# GD32E511_512 register map
File version: 1.0
CPU: CM33 r0p4, little endian, MPU, FPU, 4 interrupt priority bits
Registers are 32-bit, read-write, reset 0x0 unless marked. A register's access mark holds for its fields unless they carry their own. Offsets are from the block's base; [hi:lo] are bit positions.

## CRC — cyclic redundancy check calculation unit
Base 0x40023000
0x00 DATA reset 0xFFFFFFFF
  [31:0] DATA — CRC calculation result bits
0x04 FDATA — Free data register
  [7:0] FDATA — General-purpose 8-bit data register bits
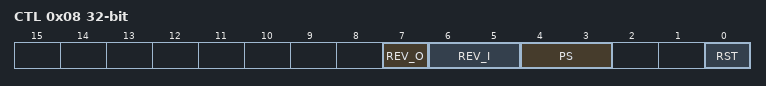
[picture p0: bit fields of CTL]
0x08 CTL — Control register
  [7] REV_O — Reverse output data
  [6:5] REV_I — Reverse input data
  [4:3] PS — Size of polynomial
  [0] RST — reset bit
0x10 IDATA reset 0xFFFFFFFF — Initialization Data Register
  [31:0] IDATA — CRC calculation initial value
0x14 POLY reset 0x4C11DB7 — Polynomial register
  [31:0] POLY — User configurable polynomial value

## DAC0 — Digital-to-analog converter
Base 0x40007400
Same registers: DAC1 0x4000CC00, DAC2 0x4000D000, DAC3 0x4000D400
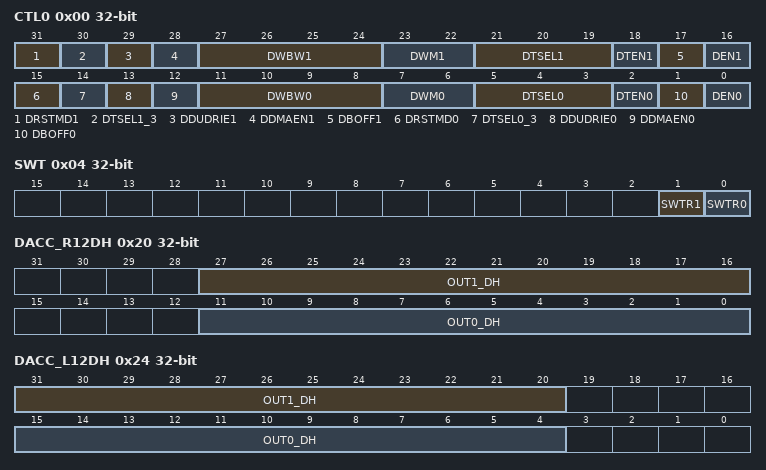
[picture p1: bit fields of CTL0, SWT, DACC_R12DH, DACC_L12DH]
0x00 CTL0 — DACx control register 0
  [31] DRSTMD1 — DACx_OUT1 reset mode
  [30] DTSEL1_3 — DACx_OUT1 trigger selection bit[3], refer to DTSEL1[2:0].
  [29] DDUDRIE1 — DACx_OUT1 DMA underrun interrupt enable
  [28] DDMAEN1 — DACx_OUT1 DMA enable
  [27:24] DWBW1 — DACx_OUT1 noise wave bit width
  [23:22] DWM1 — DACx_OUT1 noise wave mode
  [21:19] DTSEL1 — DACx_OUT1 trigger selection
  [18] DTEN1 — DACx_OUT1 trigger enable
  [17] DBOFF1 — DACx_OUT1 output buffer turn off
  [16] DEN1 — DACx_OUT1 enable
  [15] DRSTMD0 — DACx_OUT0 reset mode
  [14] DTSEL0_3 — DACx_OUT0 trigger selection bit 3, refer to DTSEL0[2:0].
  [13] DDUDRIE0 — DACx_OUT0 DMA underrun interrupt enable
  [12] DDMAEN0 — DACx_OUT0 DMA enable
  [11:8] DWBW0 — DACx_OUT0 noise wave bit width
  [7:6] DWM0 — DACx_OUT0 noise wave mode
  [5:3] DTSEL0 — DACx_OUT0 trigger selection
  [2] DTEN0 — DACx_OUT0 trigger enable
  [1] DBOFF0 — DACx_OUT0 output buffer turn off
  [0] DEN0 — DACx_OUT0 enable
0x04 SWT wo — DACx software trigger register
  [1] SWTR1 — DACx_OUT1 software trigger, cleared by hardware.
  [0] SWTR0 — DACx_OUT0 software trigger, cleared by hardware.
0x08 OUT0_R12DH — DACx_OUT0 12-bit right-aligned data holding register
  [11:0] OUT0_DH — DACx_OUT0 12-bit right-aligned data.
0x0C OUT0_L12DH — DACx_OUT0 12-bit left-aligned data holding register
  [15:4] OUT0_DH — DACx_OUT0 12-bit left-aligned data.
0x10 OUT0_R8DH — DACx_OUT0 8-bit right-aligned data holding register
  [7:0] OUT0_DH — DACx_OUT0 8-bit right-aligned data.
0x14 OUT1_R12DH — DACx_OUT1 12-bit right-aligned data holding register
  [11:0] OUT1_DH — DACx_OUT1 12-bit right-aligned data.
0x18 OUT1_L12DH — DACx_OUT1 12-bit left-aligned data holding register
  [15:4] OUT1_DH — DACx_OUT1 12-bit left-aligned data.
0x1C OUT1_R8DH — DACx_OUT1 8-bit right-aligned data holding register
  [7:0] OUT1_DH — DACx_OUT1 8-bit right-aligned data
0x20 DACC_R12DH — DACx concurrent mode 12-bit right-aligned data holding register
  [27:16] OUT1_DH — DACx_OUT1 12-bit right-aligned data
  [11:0] OUT0_DH — DACx_OUT0 12-bit right-aligned data
0x24 DACC_L12DH — DACx concurrent mode 12-bit left-aligned data holding register
  [31:20] OUT1_DH — DACx_OUT1 12-bit left-aligned data
  [15:4] OUT0_DH — DACx_OUT0 12-bit left-aligned data
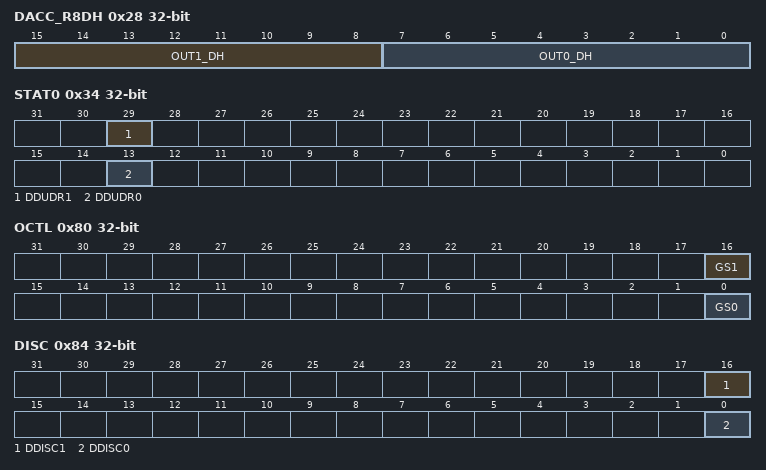
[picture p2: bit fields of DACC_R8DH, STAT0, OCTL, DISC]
0x28 DACC_R8DH — DACx concurrent mode 8-bit right-aligned data holding register
  [15:8] OUT1_DH — DACx_OUT1 8-bit right-aligned data
  [7:0] OUT0_DH — DACx_OUT0 8-bit right-aligned data
0x2C OUT0_DO ro — DACx_OUT0 data output register
  [11:0] OUT0_DO — DACx_OUT0 12-bit output data
0x30 OUT1_DO ro — DACx_OUT1 data output register
  [11:0] OUT1_DO — DACx_OUT1 12-bit output data
0x34 STAT0 — DACx status register 0
  [29] DDUDR1 — DACx_OUT1 DMA underrun flag.
  [13] DDUDR0 — DACx_OUT0 DMA underrun flag.
0x80 OCTL — DACx output control register
  [16] GS1 — DACx_OUT1 output buffer gain selection.
  [0] GS0 — DACx_OUT0 output buffer Gain selection.
0x84 DISC — DACx disconnect control register
  [16] DDISC1 — DACx_OUT1 connect GPIO selection
  [0] DDISC0 — DACx_OUT0 connect GPIO selection
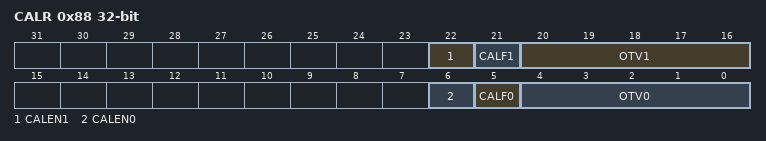
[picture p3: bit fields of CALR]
0x88 CALR access per field — DACx calibration register
  [22] CALEN1 rw — DACx_OUT1 calibration enable
  [21] CALF1 ro — DACx_OUT1 calibration offset flag. This bit is set and cleared by hardware.
  [20:16] OTV1 rw — DACx_OUT1 offset calibration value.
  [6] CALEN0 rw — DACx_OUT0 calibration enable
  [5] CALF0 ro — DACx_OUT0 calibration offset flag. This bit is set and cleared by hardware.
  [4:0] OTV0 rw — DACx_OUT0 offset calibration value.
